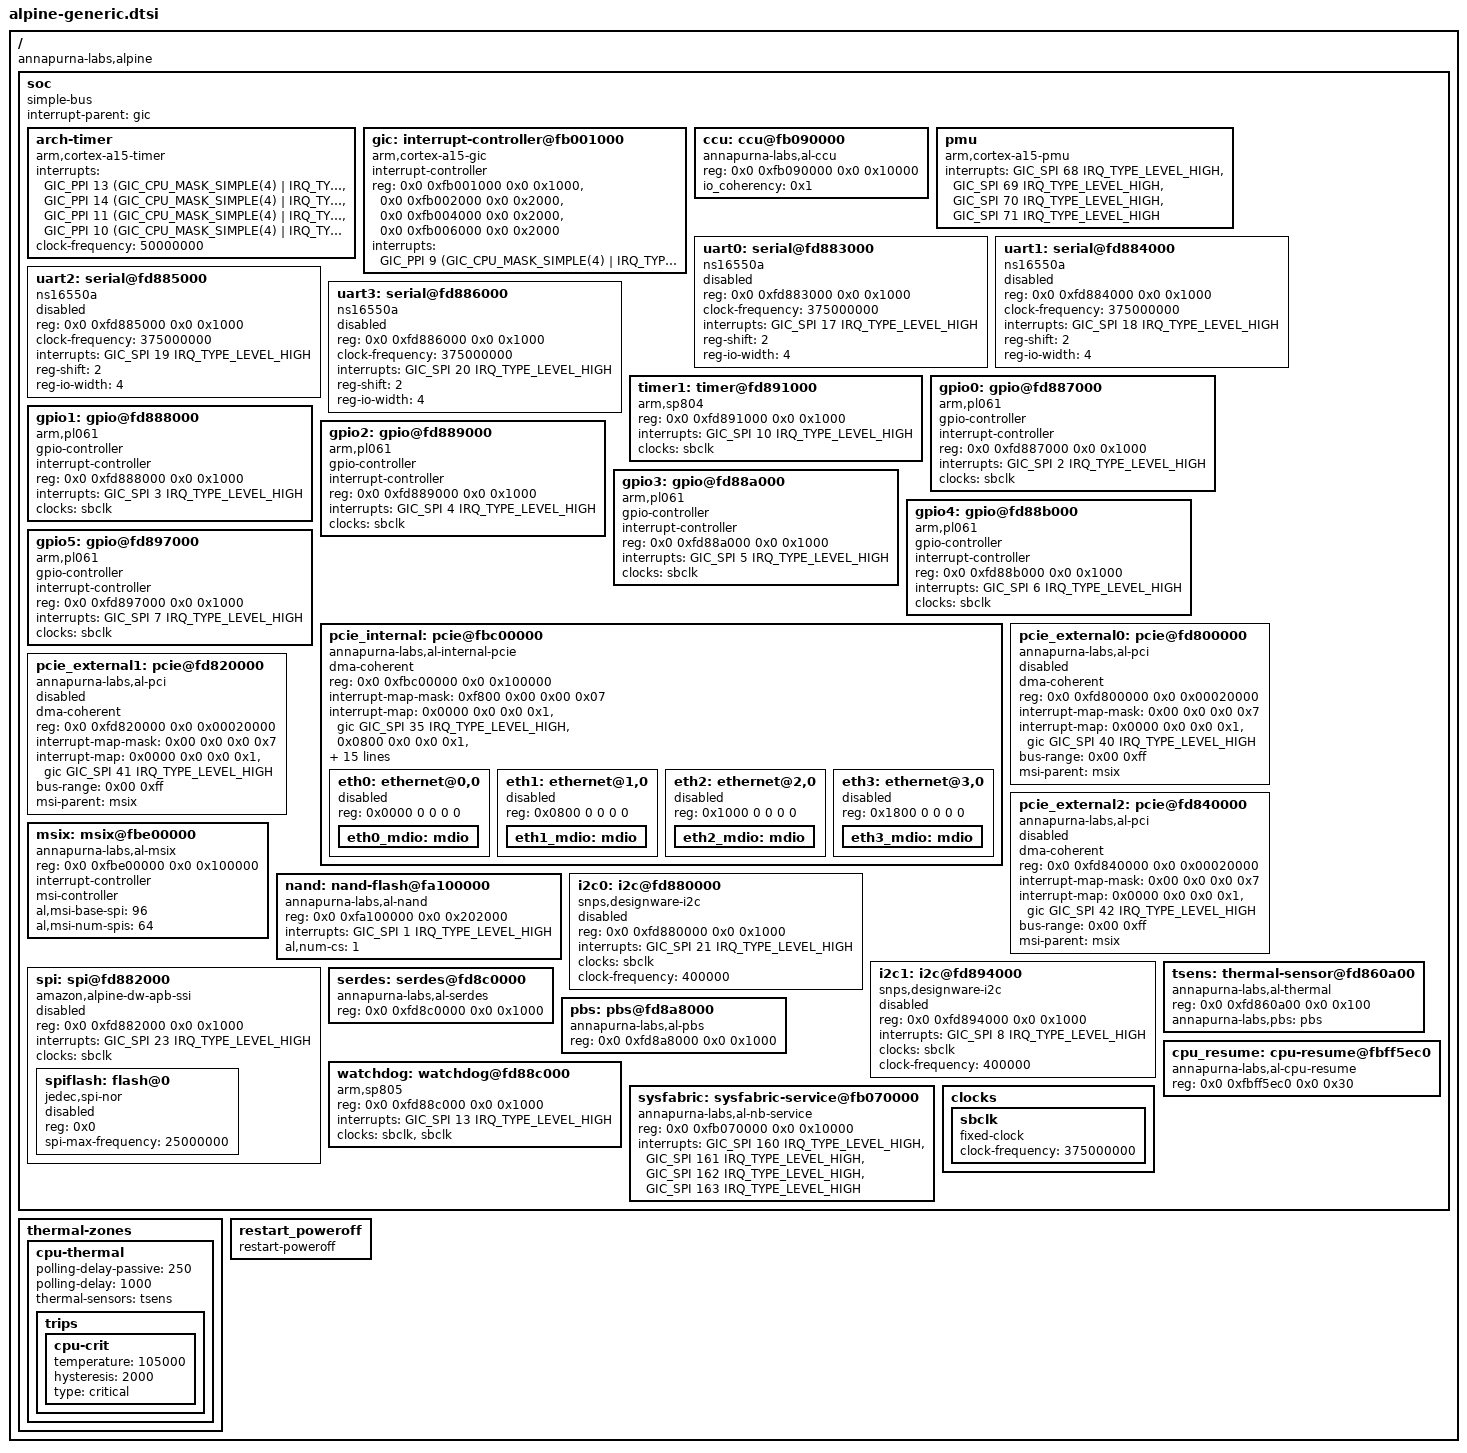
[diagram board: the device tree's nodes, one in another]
// SPDX-License-Identifier: GPL-2.0-or-later OR MIT


#include <dt-bindings/interrupt-controller/arm-gic.h>
#include <dt-bindings/interrupt-controller/irq.h>

/ {
	#address-cells = <2>;
	#size-cells = <2>;
	compatible = "annapurna-labs,alpine";

	soc: soc {
		#address-cells = <2>;
		#size-cells = <2>;
		compatible = "simple-bus";
		interrupt-parent = <&gic>;
		ranges;

		arch-timer {
			compatible = "arm,cortex-a15-timer", "arm,armv7-timer";
			interrupts =
				<GIC_PPI 13 (GIC_CPU_MASK_SIMPLE(4) | IRQ_TYPE_LEVEL_LOW)>,
				<GIC_PPI 14 (GIC_CPU_MASK_SIMPLE(4) | IRQ_TYPE_LEVEL_LOW)>,
				<GIC_PPI 11 (GIC_CPU_MASK_SIMPLE(4) | IRQ_TYPE_LEVEL_LOW)>,
				<GIC_PPI 10 (GIC_CPU_MASK_SIMPLE(4) | IRQ_TYPE_LEVEL_LOW)>;
			clock-frequency = <50000000>;
		};

		gic: interrupt-controller@fb001000 {
			compatible = "arm,cortex-a15-gic";
			#interrupt-cells = <3>;
			#size-cells = <0>;
			#address-cells = <0>;
			interrupt-controller;
			reg = <0x0 0xfb001000 0x0 0x1000>,
			      <0x0 0xfb002000 0x0 0x2000>,
			      <0x0 0xfb004000 0x0 0x2000>,
			      <0x0 0xfb006000 0x0 0x2000>;
			interrupts = <GIC_PPI 9 (GIC_CPU_MASK_SIMPLE(4) | IRQ_TYPE_LEVEL_HIGH)>;
		};

		ccu: ccu@fb090000 {
			compatible = "annapurna-labs,al-ccu";
			reg = <0x0 0xfb090000 0x0 0x10000>;
			io_coherency = <0x1>;
		};

		pmu {
			compatible = "arm,cortex-a15-pmu";
			interrupts = <GIC_SPI 68 IRQ_TYPE_LEVEL_HIGH>,
				     <GIC_SPI 69 IRQ_TYPE_LEVEL_HIGH>,
				     <GIC_SPI 70 IRQ_TYPE_LEVEL_HIGH>,
				     <GIC_SPI 71 IRQ_TYPE_LEVEL_HIGH>;
		};

		uart0: serial@fd883000 {
			compatible = "ns16550a";
			reg = <0x0 0xfd883000 0x0 0x1000>;
			clock-frequency = <375000000>;
			interrupts = <GIC_SPI 17 IRQ_TYPE_LEVEL_HIGH>;
			reg-shift = <2>;
			reg-io-width = <4>;
			status = "disabled";
		};

		uart1: serial@fd884000 {
			compatible = "ns16550a";
			reg = <0x0 0xfd884000 0x0 0x1000>;
			clock-frequency = <375000000>;
			interrupts = <GIC_SPI 18 IRQ_TYPE_LEVEL_HIGH>;
			reg-shift = <2>;
			reg-io-width = <4>;
			status = "disabled";
		};

		uart2: serial@fd885000 {
			compatible = "ns16550a";
			reg = <0x0 0xfd885000 0x0 0x1000>;
			clock-frequency = <375000000>;
			interrupts = <GIC_SPI 19 IRQ_TYPE_LEVEL_HIGH>;
			reg-shift = <2>;
			reg-io-width = <4>;
			status = "disabled";
		};

		uart3: serial@fd886000 {
			compatible = "ns16550a";
			reg = <0x0 0xfd886000 0x0 0x1000>;
			clock-frequency = <375000000>;
			interrupts = <GIC_SPI 20 IRQ_TYPE_LEVEL_HIGH>;
			reg-shift = <2>;
			reg-io-width = <4>;
			status = "disabled";
		};

		timer1: timer@fd891000 {
			compatible = "arm,sp804", "arm,primecell";
			reg = <0x0 0xfd891000 0x0 0x1000>;
			interrupts = <GIC_SPI 10 IRQ_TYPE_LEVEL_HIGH>;
			clocks = <&sbclk>;
			clock-names = "apb_pclk";
		};

		gpio0: gpio@fd887000 {
			#gpio-cells = <0x2>;
			compatible = "arm,pl061", "arm,primecell";
			gpio-controller;
			interrupt-controller;
			#interrupt-cells = <2>;
			reg = <0x0 0xfd887000 0x0 0x1000>;
			interrupts = <GIC_SPI 2 IRQ_TYPE_LEVEL_HIGH>;
			clocks = <&sbclk>;
			clock-names = "apb_pclk";
		};

		gpio1: gpio@fd888000 {
			#gpio-cells = <0x2>;
			compatible = "arm,pl061", "arm,primecell";
			gpio-controller;
			interrupt-controller;
			#interrupt-cells = <2>;
			reg = <0x0 0xfd888000 0x0 0x1000>;
			interrupts = <GIC_SPI 3 IRQ_TYPE_LEVEL_HIGH>;
			clocks = <&sbclk>;
			clock-names = "apb_pclk";
		};

		gpio2: gpio@fd889000 {
			#gpio-cells = <0x2>;
			compatible = "arm,pl061", "arm,primecell";
			gpio-controller;
			interrupt-controller;
			#interrupt-cells = <2>;
			reg = <0x0 0xfd889000 0x0 0x1000>;
			interrupts = <GIC_SPI 4 IRQ_TYPE_LEVEL_HIGH>;
			clocks = <&sbclk>;
			clock-names = "apb_pclk";
		};

		gpio3: gpio@fd88a000 {
			#gpio-cells = <0x2>;
			compatible = "arm,pl061", "arm,primecell";
			gpio-controller;
			interrupt-controller;
			#interrupt-cells = <2>;
			reg = <0x0 0xfd88a000 0x0 0x1000>;
			interrupts = <GIC_SPI 5 IRQ_TYPE_LEVEL_HIGH>;
			clocks = <&sbclk>;
			clock-names = "apb_pclk";
		};

		gpio4: gpio@fd88b000 {
			#gpio-cells = <0x2>;
			compatible = "arm,pl061", "arm,primecell";
			gpio-controller;
			interrupt-controller;
			#interrupt-cells = <2>;
			reg = <0x0 0xfd88b000 0x0 0x1000>;
			interrupts = <GIC_SPI 6 IRQ_TYPE_LEVEL_HIGH>;
			clocks = <&sbclk>;
			clock-names = "apb_pclk";
		};

		gpio5: gpio@fd897000 {
			#gpio-cells = <0x2>;
			compatible = "arm,pl061", "arm,primecell";
			gpio-controller;
			interrupt-controller;
			#interrupt-cells = <2>;
			reg = <0x0 0xfd897000 0x0 0x1000>;
			interrupts = <GIC_SPI 7 IRQ_TYPE_LEVEL_HIGH>;
			clocks = <&sbclk>;
			clock-names = "apb_pclk";
		};

		pcie_internal: pcie@fbc00000 {
			compatible = "annapurna-labs,al-internal-pcie";
			device_type = "pci";
			dma-coherent;
			#size-cells = <0x2>;
			#address-cells = <0x3>;
			#interrupt-cells = <0x1>;
			reg = <0x0 0xfbc00000 0x0 0x100000>;
			interrupt-map-mask = <0xf800 0x00 0x00 0x07>;
			interrupt-map = <0x0000 0x0 0x0 0x1 &gic GIC_SPI 35 IRQ_TYPE_LEVEL_HIGH>,
					<0x0800 0x0 0x0 0x1 &gic GIC_SPI 36 IRQ_TYPE_LEVEL_HIGH>,
					<0x1000 0x0 0x0 0x1 &gic GIC_SPI 37 IRQ_TYPE_LEVEL_HIGH>,
					<0x1800 0x0 0x0 0x1 &gic GIC_SPI 38 IRQ_TYPE_LEVEL_HIGH>,
					<0x2000 0x0 0x0 0x1 &gic GIC_SPI 39 IRQ_TYPE_LEVEL_HIGH>,
					<0x2800 0x0 0x0 0x1 &gic GIC_SPI 40 IRQ_TYPE_LEVEL_HIGH>,
					<0x4000 0x0 0x0 0x1 &gic GIC_SPI 43 IRQ_TYPE_LEVEL_HIGH>,
					<0x4800 0x0 0x0 0x1 &gic GIC_SPI 44 IRQ_TYPE_LEVEL_HIGH>;
			ranges = <0x00000000 0x0 0x00000000 0x0 0xfbc00000 0x0 0x100000>,
				 <0x02000000 0x0 0xfe000000 0x0 0xfe000000 0x0 0x1000000>;
			bus-range = <0x0 0x0>;
			msi-parent = <&msix>;

			eth0: ethernet@0,0 {
				reg = <0x0000 0 0 0 0>;
				status = "disabled";
				eth0_mdio: mdio {
					#address-cells = <1>;
					#size-cells = <0>;
				};
			};

			eth1: ethernet@1,0 {
				reg = <0x0800 0 0 0 0>;
				status = "disabled";
				eth1_mdio: mdio {
					#address-cells = <1>;
					#size-cells = <0>;
				};
			};

			eth2: ethernet@2,0 {
				reg = <0x1000 0 0 0 0>;
				status = "disabled";
				eth2_mdio: mdio {
					#address-cells = <1>;
					#size-cells = <0>;
				};
			};

			eth3: ethernet@3,0 {
				reg = <0x1800 0 0 0 0>;
				status = "disabled";
				eth3_mdio: mdio {
					#address-cells = <1>;
					#size-cells = <0>;
				};
			};
		};

		pcie_external0: pcie@fd800000 {
			compatible = "annapurna-labs,al-pci";
			device_type = "pci";
			dma-coherent;
			#size-cells = <2>;
			#address-cells = <3>;
			#interrupt-cells = <1>;
			reg = <0x0 0xfd800000 0x0 0x00020000>;
			interrupt-map-mask = <0x00 0x0 0x0 0x7>;
			interrupt-map = <0x0000 0x0 0x0 0x1 &gic GIC_SPI 40 IRQ_TYPE_LEVEL_HIGH>;
			ranges = <0x00000000 0x0 0xfb600000 0x0 0xfb600000 0x0 0x00200000>,
				 <0x01000000 0x0 0x00010000 0x0 0xe0000000 0x0 0x00010000>,
				 <0x02000000 0x0 0xe0010000 0x0 0xe0010000 0x0 0x07ff0000>;
			bus-range = <0x00 0xff>;
			msi-parent = <&msix>;
			status = "disabled";
		};

		pcie_external1: pcie@fd820000 {
			compatible = "annapurna-labs,al-pci";
			device_type = "pci";
			dma-coherent;
			#size-cells = <2>;
			#address-cells = <3>;
			#interrupt-cells = <1>;
			reg = <0x0 0xfd820000 0x0 0x00020000>;
			interrupt-map-mask = <0x00 0x0 0x0 0x7>;
			interrupt-map = <0x0000 0x0 0x0 0x1 &gic GIC_SPI 41 IRQ_TYPE_LEVEL_HIGH>;
			ranges = <0x00000000 0x0 0xfb800000 0x0 0xfb800000 0x0 0x00200000>,
				 <0x01000000 0x0 0x00020000 0x0 0xe8000000 0x0 0x00010000>,
				 <0x02000000 0x0 0xe8010000 0x0 0xe8010000 0x0 0x03ff0000>;
			bus-range = <0x00 0xff>;
			msi-parent = <&msix>;
			status = "disabled";
		};

		pcie_external2: pcie@fd840000 {
			compatible = "annapurna-labs,al-pci";
			device_type = "pci";
			dma-coherent;
			#size-cells = <2>;
			#address-cells = <3>;
			#interrupt-cells = <1>;
			reg = <0x0 0xfd840000 0x0 0x00020000>;
			interrupt-map-mask = <0x00 0x0 0x0 0x7>;
			interrupt-map = <0x0000 0x0 0x0 0x1 &gic GIC_SPI 42 IRQ_TYPE_LEVEL_HIGH>;
			ranges = <0x00000000 0x0 0xfba00000 0x0 0xfba00000 0x0 0x00200000>,
				 <0x01000000 0x0 0x00030000 0x0 0xec000000 0x0 0x00010000>,
				 <0x02000000 0x0 0xec010000 0x0 0xec010000 0x0 0x03ff0000>;
			bus-range = <0x00 0xff>;
			msi-parent = <&msix>;
			status = "disabled";
		};

		msix: msix@fbe00000 {
			compatible = "annapurna-labs,al-msix";
			reg = <0x0 0xfbe00000 0x0 0x100000>;
			interrupt-controller;
			#interrupt-cells = <0>;
			msi-controller;
			al,msi-base-spi = <96>;
			al,msi-num-spis = <64>;
		};

		nand: nand-flash@fa100000 {
			compatible = "annapurna-labs,al-nand";
			reg = <0x0 0xfa100000 0x0 0x202000>;
			interrupts = <GIC_SPI 1 IRQ_TYPE_LEVEL_HIGH>;
			al,num-cs = <1>;
			status = "okay";
		};

		i2c0: i2c@fd880000 {
			compatible = "snps,designware-i2c";
			#address-cells = <1>;
			#size-cells = <0>;
			reg = <0x0 0xfd880000 0x0 0x1000>;
			interrupts = <GIC_SPI 21 IRQ_TYPE_LEVEL_HIGH>;
			clocks = <&sbclk>;
			clock-frequency = <400000>;
			status = "disabled";
		};

		i2c1: i2c@fd894000 {
			compatible = "snps,designware-i2c";
			#address-cells = <1>;
			#size-cells = <0>;
			reg = <0x0 0xfd894000 0x0 0x1000>;
			interrupts = <GIC_SPI 8 IRQ_TYPE_LEVEL_HIGH>;
			clocks = <&sbclk>;
			clock-frequency = <400000>;
			status = "disabled";
		};

		spi: spi@fd882000 {
			compatible = "amazon,alpine-dw-apb-ssi";
			#address-cells = <0x1>;
			#size-cells = <0x0>;
			reg = <0x0 0xfd882000 0x0 0x1000>;
			interrupts = <GIC_SPI 23 IRQ_TYPE_LEVEL_HIGH>;
			clocks = <&sbclk>;
			status = "disabled";

			spiflash: flash@0 {
				#address-cells = <1>;
				#size-cells = <1>;
				compatible = "jedec,spi-nor";
				reg = <0x0>;
				spi-max-frequency = <25000000>;
				status = "disabled";
			};
		};

		tsens: thermal-sensor@fd860a00 {
			compatible = "annapurna-labs,al-thermal";
			reg = <0x0 0xfd860a00 0x0 0x100>;
			annapurna-labs,pbs = <&pbs>;
			#thermal-sensor-cells = <0>;
		};

		serdes: serdes@fd8c0000 {
			compatible = "annapurna-labs,al-serdes";
			reg = <0x0 0xfd8c0000 0x0 0x1000>;
		};

		pbs: pbs@fd8a8000 {
			compatible = "annapurna-labs,al-pbs";
			reg = <0x0 0xfd8a8000 0x0 0x1000>;
		};

		watchdog: watchdog@fd88c000 {
			compatible = "arm,sp805", "arm,primecell";
			reg = <0x0 0xfd88c000 0x0 0x1000>;
			interrupts = <GIC_SPI 13 IRQ_TYPE_LEVEL_HIGH>;
			clocks = <&sbclk>, <&sbclk>;
			clock-names = "wdog_clk", "apb_pclk";
		};

		sysfabric: sysfabric-service@fb070000 {
			compatible = "annapurna-labs,al-nb-service", "syscon";
			reg = <0x0 0xfb070000 0x0 0x10000>;
			interrupts = <GIC_SPI 160 IRQ_TYPE_LEVEL_HIGH>,
				     <GIC_SPI 161 IRQ_TYPE_LEVEL_HIGH>,
				     <GIC_SPI 162 IRQ_TYPE_LEVEL_HIGH>,
				     <GIC_SPI 163 IRQ_TYPE_LEVEL_HIGH>;
		};

		cpu_resume: cpu-resume@fbff5ec0 {
			compatible = "annapurna-labs,al-cpu-resume";
			reg = <0x0 0xfbff5ec0 0x0 0x30>;
		};

		clocks {
			#address-cells = <0x1>;
			#size-cells = <0x0>;

			sbclk: sbclk {
				#clock-cells = <0x0>;
				compatible = "fixed-clock";
				clock-frequency = <375000000>;
			};
		};
	};

	thermal-zones {
		cpu-thermal {
			polling-delay-passive = <250>;
			polling-delay = <1000>;
			thermal-sensors = <&tsens>;

			trips {
				cpu-crit {
					temperature = <105000>;
					hysteresis = <2000>;
					type = "critical";
				};
			};
		};
	};

	restart_poweroff {
		compatible = "restart-poweroff";
	};
};
